# STM32H7B0xxQ register map
File version: 1.0
Registers are 32-bit, read-write, reset 0x0 unless marked. A register's access mark holds for its fields unless they carry their own. Offsets are from the block's base; [hi:lo] are bit positions; {n}, {i} and the like mark numbered series.

## WWDG1 — Window WATCHDOG
Base 0x50003000
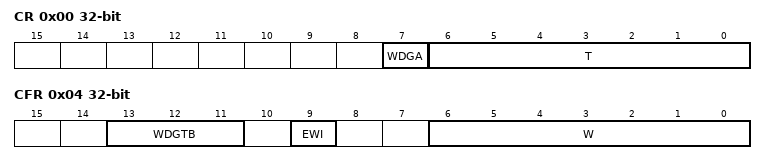
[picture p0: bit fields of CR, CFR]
0x00 CR — WWDG Control register
  [7] WDGA — Activation bit
  [6:0] T — T[6:0] bits (7-Bit counter (MSB to LSB))
0x04 CFR — WWDG Configuration register
  [13:11] WDGTB — WDGTB[2:0] bits (Timer Base)
    0=PRESCALER_1 (WWDG counter clock = (PCLK1/4096)/1); 1=PRESCALER_2 (WWDG counter clock = (PCLK1/4096)/2); 2=PRESCALER_4 (WWDG counter clock = (PCLK1/4096)/4); 3=PRESCALER_8 (WWDG counter clock = (PCLK1/4096)/8); 4=PRESCALER_16 (WWDG counter clock = (PCLK1/4096)/16); 5=PRESCALER_32 (WWDG counter clock = (PCLK1/4096)/32); 6=PRESCALER_64 (WWDG counter clock = (PCLK1/4096)/64); 7=PRESCALER_128 (WWDG counter clock = (PCLK1/4096)/128)
  [9] EWI — Early Wakeup Interrupt
  [6:0] W — W[6:0] bits (7-bit window value)
0x08 SR — WWDG Status register
  [0] EWIF — Early Wakeup Interrupt Flag

## GPV — Global Programmer View
Base 0x51000000
0x1FD0 AXI_PERIPH_ID_4 — AXI interconnect - peripheral ID4 register
{0x1FC0+4i} AXI_PERIPH_ID_{i} (i=5..7) — Reserved
{0x1FE0+4i} AXI_PERIPH_ID_{i} (i=0..3) — AXI interconnect - peripheral ID{i} register
{0x1FF0+4i} AXI_COMP_ID_{i} (i=0..3) — AXI interconnect - component ID{i} register
{0x1008+0x1000*i} AXI_TARG{i}_FN_MOD_ISS_BM (i=1..10) — AXI interconnect - TARG {i} bus matrix issuing functionality register
0x2024 AXI_TARG1_FN_MOD2 — AXI interconnect - TARG 1 bus matrix functionality 2 register
0x202C AXI_TARG1_FN_MOD_LB — AXI interconnect - TARG 1 long burst functionality modification register
0x2108 AXI_TARG1_FN_MOD — AXI interconnect - TARG 1 issuing functionality modification register
0x3024 AXI_TARG2_FN_MOD2 — AXI interconnect - TARG 2 bus matrix functionality 2 register
0x302C AXI_TARG2_FN_MOD_LB — AXI interconnect - TARG 2 long burst functionality modification register
0x3108 AXI_TARG2_FN_MOD — AXI interconnect - TARG 2 issuing functionality modification register
{0x1024+0x1000*i} AXI_TARG{i}_FN_MOD2 (i=7..10) — AXI interconnect - TARG {i} bus matrix functionality 2 register
0x802C AXI_TARG7_FN_MOD_LB — AXI interconnect - TARG 7 long burst functionality modification register
{0x1108+0x1000*i} AXI_TARG{i}_FN_MOD (i=7..10) — AXI interconnect - TARG {i} issuing functionality modification register
0xC02C AXI_TARG10_FN_MOD_LB — AXI interconnect - TARG 10 long burst functionality modification register
0x42024 AXI_INI1_FN_MOD2 — AXI interconnect - INI 1 functionality modification 2 register
0x42028 AXI_INI1_FN_MOD_AHB — AXI interconnect - INI 1 AHB functionality modification register
{0x41100+0x1000*i} AXI_INI{i}_READ_QOS (i=1..7) — AXI interconnect - INI {i} read QoS register
{0x41104+0x1000*i} AXI_INI{i}_WRITE_QOS (i=1..7) — AXI interconnect - INI {i} write QoS register
{0x41108+0x1000*i} AXI_INI{i}_FN_MOD (i=1..7) — AXI interconnect - INI {i} issuing functionality modification register
0x44024 AXI_INI3_FN_MOD2 — AXI interconnect - INI 3 functionality modification 2 register
0x44028 AXI_INI3_FN_MOD_AHB — AXI interconnect - INI 3 AHB functionality modification register
0x48024 AXI_INI7_FN_MOD2 — AXI interconnect - INI 7 functionality modification 2 register
0x48028 AXI_INI7_FN_MOD_AHB — AXI interconnect - INI 7 AHB functionality modification register

## MDMA — MDMA Controller
Base 0x52000000
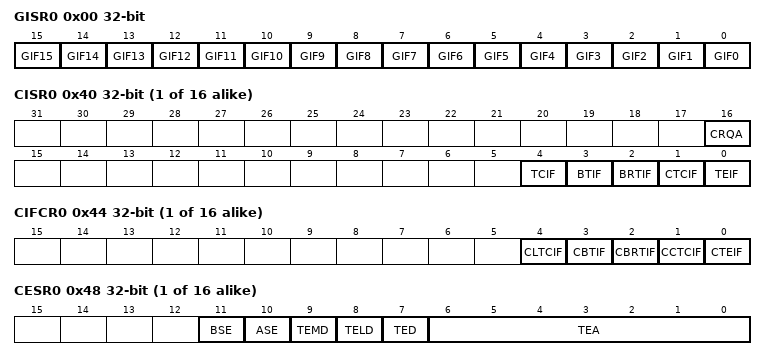
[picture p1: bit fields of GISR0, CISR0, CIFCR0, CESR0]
0x00 GISR0 — MDMA Global Interrupt/Status Register 0
  [n] GIF{n} (n=0..15) — Channel {n} global interrupt flag
{0x40+0x40*i} CISR{i} (i=0..15) — MDMA channel x interrupt/status register
  [16] CRQA — Channel x request Active flag
  [4] TCIF — Channel x buffer transfer complete interrupt flag
  [3] BTIF — Channel x block transfer complete interrupt flag
  [2] BRTIF — Channel x block repeat transfer complete interrupt flag
  [1] CTCIF — Channel x Channel Transfer Complete interrupt flag
  [0] TEIF — Channel x transfer error interrupt flag
{0x44+0x40*i} CIFCR{i} (i=0..15) — MDMA channel x interrupt flag clear register
  [4] CLTCIF — CLear Transfer buffer Complete Interrupt Flag for channel
  [3] CBTIF — Channel x Clear block transfer complete interrupt flag
  [2] CBRTIF — Channel x clear block repeat transfer complete interrupt flag
  [1] CCTCIF — Clear Channel transfer complete interrupt flag for channel x
  [0] CTEIF — Channel x clear transfer error interrupt flag
{0x48+0x40*i} CESR{i} (i=0..15) — MDMA Channel x error status register
  [11] BSE — Block Size Error
  [10] ASE — Address/Size Error
  [9] TEMD — Transfer Error Mask Data
  [8] TELD — Transfer Error Link Data
  [7] TED — Transfer Error Direction
  [6:0] TEA — Transfer Error Address
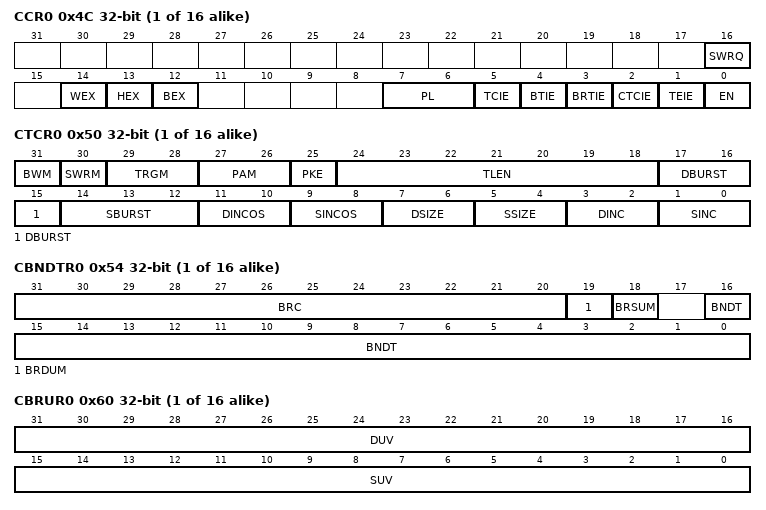
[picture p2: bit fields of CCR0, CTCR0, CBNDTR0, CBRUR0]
{0x4C+0x40*i} CCR{i} (i=0..15) — MDMA channel x control register
  [16] SWRQ — SW ReQuest
  [14] WEX — Word Endianness eXchange
  [13] HEX — Half word Endianness eXchange
  [12] BEX — Byte Endianness eXchange
  [7:6] PL — Priority level
  [5] TCIE — buffer Transfer Complete interrupt enable
  [4] BTIE — Block Transfer interrupt enable
  [3] BRTIE — Block Repeat transfer interrupt enable
  [2] CTCIE — Channel Transfer Complete interrupt enable
  [1] TEIE — Transfer error interrupt enable
  [0] EN — Channel enable / flag channel ready when read low
{0x50+0x40*i} CTCR{i} (i=0..15) — MDMA channel x Transfer Configuration register
  [31] BWM — Bufferable Write Mode
  [30] SWRM — SW Request Mode
  [29:28] TRGM — Trigger Mode
  [27:26] PAM — Padding/Alignment Mode
  [25] PKE — PacK Enable
  [24:18] TLEN — buffer Transfer Length (number of bytes - 1)
  [17:15] DBURST — Destination burst transfer configuration
  [14:12] SBURST — Source burst transfer configuration
  [11:10] DINCOS — Destination increment offset size
  [9:8] SINCOS — Source increment offset size
  [7:6] DSIZE — Destination data size
  [5:4] SSIZE — Source data size
  [3:2] DINC — Source increment mode
  [1:0] SINC — Source increment mode
{0x54+0x40*i} CBNDTR{i} (i=0..15) — MDMA Channel x block number of data register
  [31:20] BRC — Block Repeat Count
  [19] BRDUM — Block Repeat Destination address Update Mode
  [18] BRSUM — Block Repeat Source address Update Mode
  [16:0] BNDT — Block Number of data bytes to transfer
{0x58+0x40*i} CSAR{i} (i=0..15) — MDMA channel x source address register
  [31:0] SAR — Source address
{0x5C+0x40*i} CDAR{i} (i=0..15) — MDMA channel x destination address register
  [31:0] DAR — Destination address
{0x60+0x40*i} CBRUR{i} (i=0..15) — MDMA channel x Block Repeat address Update register
  [31:16] DUV — Destination address Update Value
  [15:0] SUV — Source address Update Value
{0x64+0x40*i} CLAR{i} (i=0..15) — MDMA channel x Link Address register
  [31:0] LAR — Link Address Register
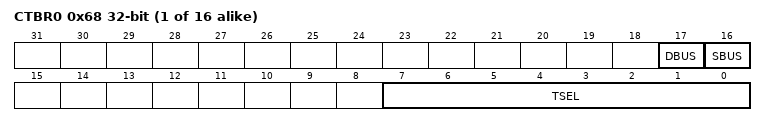
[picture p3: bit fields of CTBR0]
{0x68+0x40*i} CTBR{i} (i=0..15) — MDMA channel x Trigger and Bus selection Register
  [17] DBUS — Destination BUS select
  [16] SBUS — Source BUS select
  [7:0] TSEL — Trigger SELection
{0x70+0x40*i} CMAR{i} (i=0..15) — MDMA channel x Mask address register
  [31:0] MAR — Mask address
{0x74+0x40*i} CMDR{i} (i=0..15) — MDMA channel x Mask Data register
  [31:0] MDR — Mask Data
